# Template register map
Vendor: VendorName Co.Ltd; Series: SeriesName; File version: 1.2
CPU: CM7 r0p1, little endian, MPU, FPU, 4 interrupt priority bits
Registers are 32-bit, read-write, no defined reset value unless marked. A register's access mark holds for its fields unless they carry their own. Offsets are from the block's base; [hi:lo] are bit positions; lines under a group give offsets from that group; {n}, {i} and the like mark numbered series.

## EDMA1 — Enhanced Direct Memory Access 1
Base 0x400B8000
Same registers: EDMA2 0x40094000
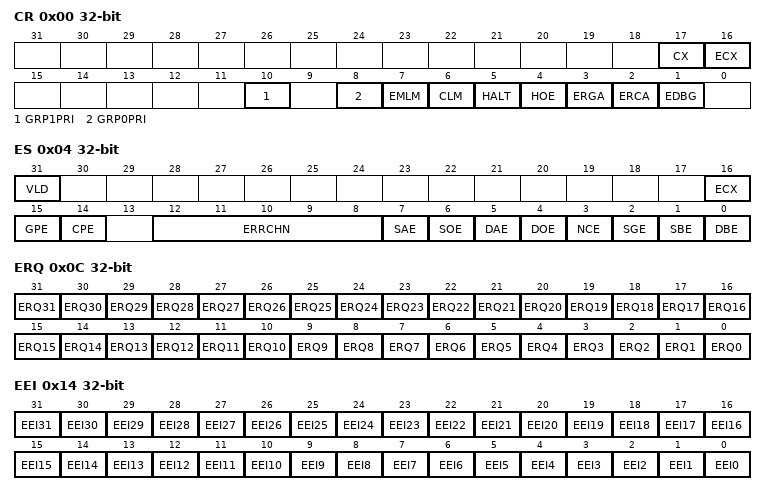
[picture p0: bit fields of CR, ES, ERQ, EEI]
0x00 CR — DMA control register
  [17] CX — EDMA CX bit: cancel transfer
  [16] ECX — EDMA ECX bit: error cancel transfer
  [10] GRP1PRI — EDMA GRP1PRI bit: channel group 1 priority
  [8] GRP0PRI — EDMA GRP0PRI bit: channel group 0 priority
  [7] EMLM — EDMA EMLM bit: enable minor loop mapping
  [6] CLM — EDMA CLM bit: continuous link mode
  [5] HALT — EDMA HALT bit: halt EDMA operations
  [4] HOE — EDMA HOE bit: halt on error
  [3] ERGA — EDMA ERGA bit: enable round robin group arbitration
  [2] ERCA — EDMA ERCA bit: enable round robin channel arbitration
  [1] EDBG — EDMA EDBG bit: enable debug
0x04 ES ro — DMA error status register
  [31] VLD — EDMA VLD bit: logical OR of all ERR status fields
  [16] ECX — EDMA ECX bit: transfer canceled
  [15] GPE — EDMA GPE bit: group Priority error
  [14] CPE — EDMA CPE bit: channel priority error
  [12:8] ERRCHN — EDMA ERRCHN[4:0] bit: error channel number or canceled channel number
  [7] SAE — EDMA SAE bit: source address error
  [6] SOE — EDMA SOE bit: source offset error
  [5] DAE — EDMA DAE bit: destination address error
  [4] DOE — EDMA DOE bit: destination offset error
  [3] NCE — EDMA NCE bit: NBYTES or CITER configuration error
  [2] SGE — EDMA SGE bit: scatter or gather configuration error
  [1] SBE — EDMA SBE bit: source bus error
  [0] DBE — EDMA DBE bit: destination bus error
0x0C ERQ — DMA enable request register
  [n] ERQ{n} (n=0..31) — EDMA ERQ{n} bit: enable DMA request {n}
0x14 EEI — DMA enable error interrupt register
  [n] EEI{n} (n=0..31) — EDMA EEI{n} bit: enable error interrupt {n}
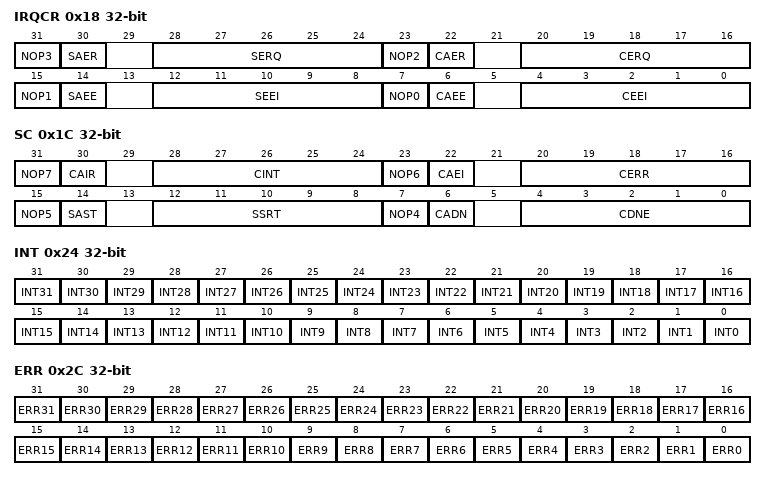
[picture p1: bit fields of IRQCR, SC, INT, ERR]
0x18 IRQCR wo — DMA interrupt request control register
  [8n+7] NOP{n} (n=0..3) — EDMA NOP{n} bit: no operation enable bit {n}
  [30] SAER — EDMA SAER bit: set all enable request bit
  [28:24] SERQ — EDMA SERQ[4:0] bit: set enable request bit
  [22] CAER — EDMA CAER bit: clear all enable request bit
  [20:16] CERQ — EDMA CERQ[4:0] bit: clearenable request bit
  [14] SAEE — EDMA SAEE bit: set all error interrupt enable bit
  [12:8] SEEI — EDMA SEEI[4:0] bit: set error interrupt enable bit
  [6] CAEE — EDMA CAEE bit: clear all error request bit
  [4:0] CEEI — EDMA CEEI[4:0] bit: clear error interrupt enable bit
0x18 CEEI 8-bit (alternate view of IRQCR) — DMA clear enable error interrupt register
0x19 SEEI 8-bit (alternate view of IRQCR) — DMA set enable error interrupt register
0x1A CERQ 8-bit (alternate view of IRQCR) — DMA clear enable request register
0x1B SERQ 8-bit (alternate view of IRQCR) — DMA set enable request register
0x1C SC wo — DMA start clear register
  [8n-25] NOP{n} (n=4..7) — EDMA NOP{n} bit: no operation enable bit {n}
  [30] CAIR — EDMA CAIR bit: clear all interrupt request bit
  [28:24] CINT — EDMA CINT[4:0] bit: clear error interrupt enable bit
  [22] CAEI — EDMA CAEI bit: clear all error instructions bit
  [20:16] CERR — EDMA CERR[4:0] bit: clear error intstructions bit
  [14] SAST — EDMA SAST bit: set all START bit
  [12:8] SSRT — EDMA SSRT[4:0] bit: set START bit
  [6] CADN — EDMA CADN bit: clear all DONE bit
  [4:0] CDNE — EDMA CDNE[4:0] bit: clear DONE bit
0x1C CDNE 8-bit (alternate view of SC) — DMA clear DONE status bit register
0x1D SSRT 8-bit (alternate view of SC) — DMA set START bit register
0x1E CERR 8-bit (alternate view of SC) — DMA clear error register
0x1F CINT 8-bit (alternate view of SC) — DMA clear interrupt request register
0x24 INT — DMA interrupt request register
  [n] INT{n} (n=0..31) — EDMA INT{n} bit: interrupt request {n}
0x2C ERR — DMA error register
  [n] ERR{n} (n=0..31) — EDMA ERR{n} bit: error in channel {n}
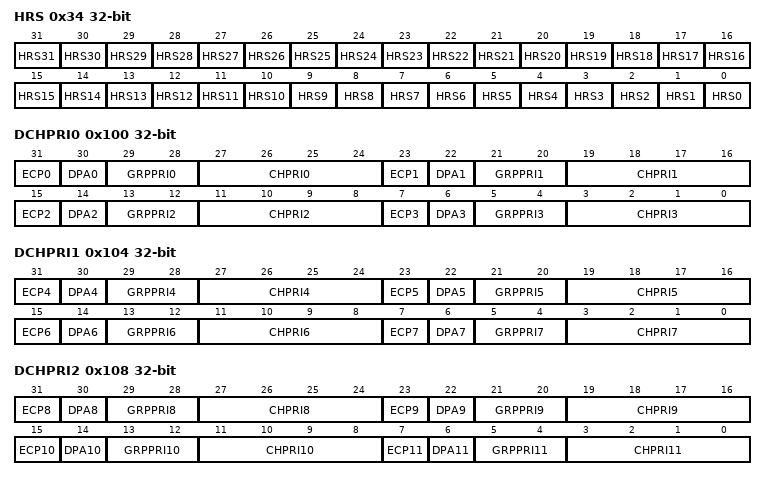
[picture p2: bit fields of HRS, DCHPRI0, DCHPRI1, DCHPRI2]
0x34 HRS ro — DMA hardware request status register
  [n] HRS{n} (n=0..31) — EDMA HRS{n} bit: hardware request status channel {n}
0x100 DCHPRI0 — DMA channel priority register 0
  [31-8n] ECP{n} (n=0..3) — EDMA ECP{n} bit: enable channel {n} preemption
  [30-8n] DPA{n} (n=0..3) — EDMA DPA{n} bit: disable preempt ability {n}
  [29-8n:28-8n] GRPPRI{n} ro (n=0..3) — EDMA GRPPRI{n}[1:0] bit: channel {n} current group priority
  [27-8n:24-8n] CHPRI{n} (n=0..3) — EDMA CHPRI{n}[3:0] bit: channel {n} arbitration priority
0x104 DCHPRI1 — DMA channel priority register 1
  [63-8n] ECP{n} (n=4..7) — EDMA ECP{n} bit: enable channel {n} preemption
  [62-8n] DPA{n} (n=4..7) — EDMA DPA{n} bit: disable preempt ability {n}
  [61-8n:60-8n] GRPPRI{n} ro (n=4..7) — EDMA GRPPRI{n}[1:0] bit: channel {n} current group priority
  [59-8n:56-8n] CHPRI{n} (n=4..7) — EDMA CHPRI{n}[3:0] bit: channel {n} arbitration priority
0x108 DCHPRI2 — DMA channel priority register 2
  [95-8n] ECP{n} (n=8..11) — EDMA ECP{n} bit: enable channel {n} preemption
  [94-8n] DPA{n} (n=8..11) — EDMA DPA{n} bit: disable preempt ability {n}
  [93-8n:92-8n] GRPPRI{n} ro (n=8..11) — EDMA GRPPRI{n}[1:0] bit: channel {n} current group priority
  [91-8n:88-8n] CHPRI{n} (n=8..11) — EDMA CHPRI{n}[3:0] bit: channel {n} arbitration priority
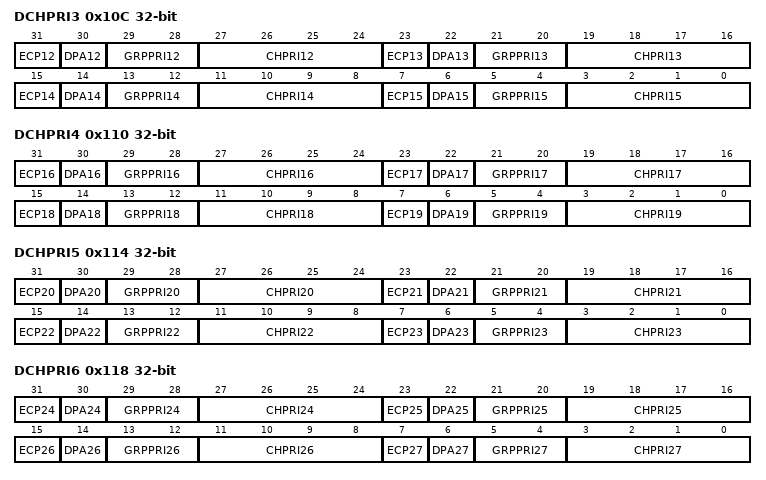
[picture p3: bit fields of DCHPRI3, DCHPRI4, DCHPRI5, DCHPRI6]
0x10C DCHPRI3 — DMA channel priority register 3
  [127-8n] ECP{n} (n=12..15) — EDMA ECP{n} bit: enable channel {n} preemption
  [126-8n] DPA{n} (n=12..15) — EDMA DPA{n} bit: disable preempt ability {n}
  [125-8n:124-8n] GRPPRI{n} ro (n=12..15) — EDMA GRPPRI{n}[1:0] bit: channel {n} current group priority
  [123-8n:120-8n] CHPRI{n} (n=12..15) — EDMA CHPRI{n}[3:0] bit: channel {n} arbitration priority
0x110 DCHPRI4 — DMA channel priority register 4
  [159-8n] ECP{n} (n=16..19) — EDMA ECP{n} bit: enable channel {n} preemption
  [158-8n] DPA{n} (n=16..19) — EDMA DPA{n} bit: disable preempt ability {n}
  [157-8n:156-8n] GRPPRI{n} ro (n=16..19) — EDMA GRPPRI{n}[1:0] bit: channel {n} current group priority
  [155-8n:152-8n] CHPRI{n} (n=16..19) — EDMA CHPRI{n}[3:0] bit: channel {n} arbitration priority
0x114 DCHPRI5 — DMA channel priority register 5
  [191-8n] ECP{n} (n=20..23) — EDMA ECP{n} bit: enable channel {n} preemption
  [190-8n] DPA{n} (n=20..23) — EDMA DPA{n} bit: disable preempt ability {n}
  [189-8n:188-8n] GRPPRI{n} ro (n=20..23) — EDMA GRPPRI{n}[1:0] bit: channel {n} current group priority
  [187-8n:184-8n] CHPRI{n} (n=20..23) — EDMA CHPRI{n}[3:0] bit: channel {n} arbitration priority
0x118 DCHPRI6 — DMA channel priority register 6
  [223-8n] ECP{n} (n=24..27) — EDMA ECP{n} bit: enable channel {n} preemption
  [222-8n] DPA{n} (n=24..27) — EDMA DPA{n} bit: disable preempt ability {n}
  [221-8n:220-8n] GRPPRI{n} ro (n=24..27) — EDMA GRPPRI{n}[1:0] bit: channel {n} current group priority
  [219-8n:216-8n] CHPRI{n} (n=24..27) — EDMA CHPRI{n}[3:0] bit: channel {n} arbitration priority
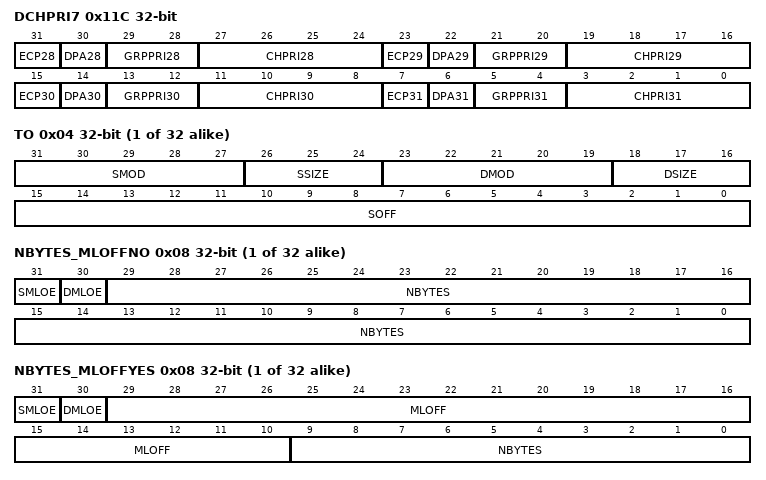
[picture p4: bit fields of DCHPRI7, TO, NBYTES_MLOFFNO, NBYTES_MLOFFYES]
0x11C DCHPRI7 — DMA channel priority register 7
  [255-8n] ECP{n} (n=28..31) — EDMA ECP{n} bit: enable channel {n} preemption
  [254-8n] DPA{n} (n=28..31) — EDMA DPA{n} bit: disable preempt ability {n}
  [253-8n:252-8n] GRPPRI{n} ro (n=28..31) — EDMA GRPPRI{n}[1:0] bit: channel {n} current group priority
  [251-8n:248-8n] CHPRI{n} (n=28..31) — EDMA CHPRI{n}[3:0] bit: channel {n} arbitration priority
{0x1000+0x20*i} TCD[{i}] (i=0..31) group — Grouping of TCD
  0x00 SADDR — TCD source address register
    [31:0] SADDR — EDMA SADDR[31:0] bit: source address
  0x04 TO — TCD transfer offset register
    [31:27] SMOD — EDMA SMOD[4:0] bit: source address mode
    [26:24] SSIZE — EDMA SSIZE[2:0] bit: source data transmit size
    [23:19] DMOD — EDMA DMOD[4:0] bit: data address mode
    [18:16] DSIZE — EDMA DSIZE[2:0] bit: data transmit size
    [15:0] SOFF — EDMA SOFF[15:0] bit: source address signed offset
  0x08 NBYTES — TCD minor byte count register
  0x08 NBYTES_MLNO (alternate view of NBYTES) — TCD minor byte count register 1
    [31:0] NBYTES — EDMA NBYTES[31:0] bit: minor byte transfer count
  0x08 NBYTES_MLOFFNO (alternate view of NBYTES) — TCD minor byte count register 2
    [31] SMLOE — EDMA SMLOE bit: source minor loop offset enable
    [30] DMLOE — EDMA DMLOE bit: destination minor loop offset enable
    [29:0] NBYTES — EDMA NBYTES[29:0] bit: minor byte transfer count
  0x08 NBYTES_MLOFFYES (alternate view of NBYTES) — TCD minor byte count register 3
    [31] SMLOE — EDMA SMLOE bit: source minor loop offset enable
    [30] DMLOE — EDMA DMLOE bit: destination minor loop offset enable
    [29:10] MLOFF — EDMA MLOFF[19:0] bit: minor loop sign-extended offset
    [9:0] NBYTES — EDMA NBYTES[9:0] bit: minor byte transfer count
  0x0C SLAST — TCD last source address adjustment register
    [31:0] SLAST — EDMA SLAST[31:0] bit: last source address adjustment
  0x10 DADDR — TCD destination address register
    [31:0] DADDR — EDMA DADDR[31:0] bit: destination address
  0x14 CITER — TCD current loop link count/destination address offset register
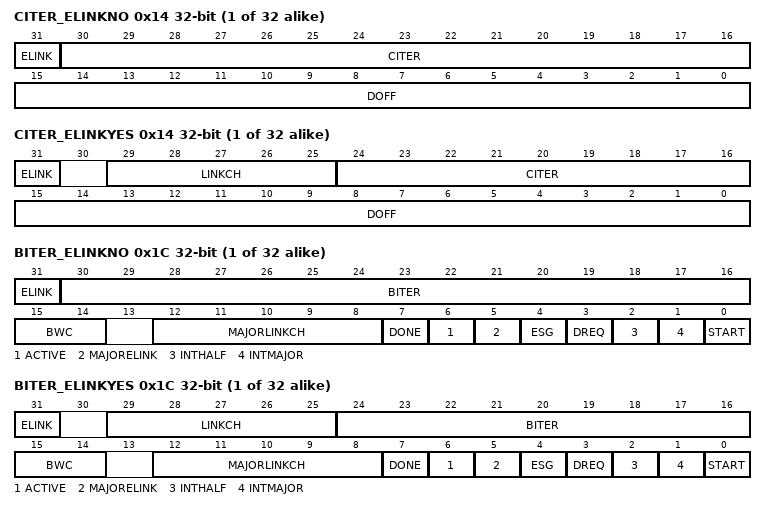
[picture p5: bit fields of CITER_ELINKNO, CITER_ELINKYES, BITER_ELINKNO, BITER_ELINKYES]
  0x14 CITER_ELINKNO (alternate view of CITER) — TCD current loop link count/destination address offset register 1
    [31] ELINK — EDMA ELINK bit: enable channel-to-channel linking on minor-loop complete
    [30:16] CITER — EDMA CITER[14:0] bit: current major iteration count
    [15:0] DOFF — EDMA DOFF[15:0] bit: destination address signed offset
  0x14 CITER_ELINKYES (alternate view of CITER) — TCD current loop link count/destination address offset register 2
    [31] ELINK — EDMA ELINK bit: enable channel-to-channel linking on minor-loop complete
    [29:25] LINKCH — EDMA LINKCH[4:0] bit: minor loop link channel number
    [24:16] CITER — EDMA CITER[8:0] bit: current major iteration count
    [15:0] DOFF — EDMA DOFF[15:0] bit: destination address signed offset
  0x18 DLASTSGA — TCD last destination/store address adjustment register
    [31:0] DLASTSGA — EDMA DLASTSGA[31:0] bit: destination last address adjustment
  0x1C BITER — TCD beginning loop link count/status control register
  0x1C BITER_ELINKNO (alternate view of BITER) — TCD beginning loop link count/status control register 1
    [31] ELINK — EDMA ELINK bit: enables channel-to-channel linking on minor loop complete
    [30:16] BITER — EDMA BITER[14:0] bit: starting major iteration count
    [15:14] BWC — EDMA BWC[1:0] bit: bandwidth control
    [12:8] MAJORLINKCH — EDMA MAJORLINKCH[4:0] bit: major loop link channel number
    [7] DONE — EDMA DONE bit: channel done
    [6] ACTIVE ro — EDMA ACTIVE bit: channel active
    [5] MAJORELINK — EDMA MAJORELINK bit: enable channel-to-channel linking on major loop complete
    [4] ESG — EDMA ESG bit: enable scatter or gather processing
    [3] DREQ — EDMA DREQ bit: disable request
    [2] INTHALF — EDMA INTHALF bit: enable an interrupt when major counter is half complete
    [1] INTMAJOR — EDMA INTMAJOR bit: enable an interrupt when major iteration count completes
    [0] START — EDMA START bit: channel start
  0x1C BITER_ELINKYES (alternate view of BITER) — TCD beginning loop link count/status control register 2
    [31] ELINK — EDMA ELINK bit: enables channel-to-channel linking on minor loop complete
    [29:25] LINKCH — EDMA LINKCH[4:0] bit: link channel number
    [24:16] BITER — EDMA BITER[8:0] bit: starting major iteration count
    [15:14] BWC — EDMA BWC[1:0] bit: bandwidth control
    [12:8] MAJORLINKCH — EDMA MAJORLINKCH[4:0] bit: major loop link channel number
    [7] DONE — EDMA DONE bit: channel done
    [6] ACTIVE ro — EDMA ACTIVE bit: channel active
    [5] MAJORELINK — EDMA MAJORELINK bit: enable channel-to-channel linking on major loop complete
    [4] ESG — EDMA ESG bit: enable scatter or gather processing
    [3] DREQ — EDMA DREQ bit: disable request
    [2] INTHALF — EDMA INTHALF bit: enable an interrupt when major counter is half complete
    [1] INTMAJOR — EDMA INTMAJOR bit: enable an interrupt when major iteration count completes
    [0] START — EDMA START bit: channel start
